# DP32G030 register map
File version: 1.0
CPU: CM0 r0p0, little endian, no MPU, no FPU, 4 interrupt priority bits
Registers are 32-bit, read-write, reset 0x0 unless marked. A register's access mark holds for its fields unless they carry their own. Offsets are from the block's base; [hi:lo] are bit positions; {n}, {i} and the like mark numbered series.

## AES128 — AES128 unit
Base 0x400BD000
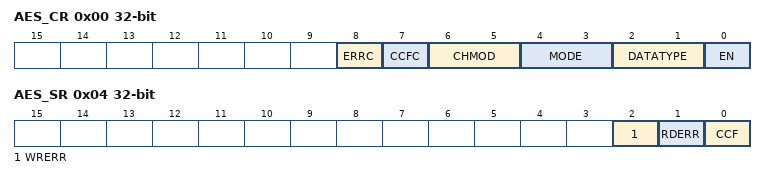
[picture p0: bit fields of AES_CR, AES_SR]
0x00 AES_CR access per field — AES control register
  [8] ERRC rw — Error Flag Clear Writing a 1 to this bit will clear the RDERR and WRERR flags. This bit reads low.
  [7] CCFC wo — The computation complete flag is cleared. This bit reads low.
  [6:5] CHMOD rw — AES link mode selection. 00: Electronic Codebook (ECB) 01: Cipher Block Link (CBC) 10: Counter mode (CTR) The AES link mode can only be changed when AES is disabled. Writing these bits when AES is enabled is prohibited to avoid unpredictable AES behaviour.
  [4:3] MODE rw — AES mode selection. 00: Mode 1: Encryption 01: Mode II: Key Derivation 10: Mode III: Decryption 11: Mode 4: Key Derivation + Decryption The mode of operation can only be changed when AES is disabled. Disable writing these bits when AES is enabled to avoid unpredictable AES behaviour. If CTR mode is selected, mode 4 is disabled. if the software attempts to configure mode 4 for CTR mode, it will force mode 3.
  [2:1] DATATYPE rw — Data type selection. 00: 32-bit data, no bit exchange. 01: 16-bit data or half-word, half-word exchange is performed. For example, the original data 0x764356AB, the value given to the encryption block is 0x56AB7643 10: 8-bit data or byte, all bytes are exchanged. For example, the original data is 0x764356AB and the value given to the encryption block is 0xAB564376. 11: 1-bit data. All bits are exchanged. For example, the original data is 0x00112233, the value given to the encryption block is 0xCC448800 The operation mode can be changed only when AES is disabled. It is forbidden to write these bits when AES is enabled to avoid some unpredictable AES behaviour.
  [0] EN rw — AES enable signal. The AES can be initialised at any time by resetting this bit: The AES is ready to start processing new blocks when EN is set. This bit is automatically cleared by hardware when the AES completes operation in mode 2 (key derivation).
0x04 AES_SR ro — AES status register
  [2] WRERR — Write Error Flag. This bit is set by hardware when an unexpected read operation from the AES_DINR register is detected (during the calculation or data entry phase). Software clears it by setting the ERRC bit in the AES_CR register. 0: No write error detected 1: Write error detected This flag has no effect on the AES, which continues to operate even if a WRERR interrupt is generated.
  [1] RDERR — Read Error Flag. This bit is set by hardware when an unexpected read operation from the AES_DOUTR register is detected (during the calculation or data entry phase). Software clears it by setting the ERRC bit in the AES_CR register. 0: No read error detected 1: Read error detected This flag has no effect on the AES, which continues to operate even if an RDERR interrupt is generated.
  [0] CCF — Calculation Completion Flag. If the CCFIE bit was previously set in the AES_CR register. Software clears it by setting the CCFC bit in the AES_CR register. 1: Calculation complete 0: Calculation not completed
0x08 AES_DINR — AES input data register
  [31:0] DINR — Input data register. In the input stage, this register must be written four times: - In mode 1 (encryption), four bytes must be written, representing data from MSB to LSB. - In mode 2 (key derivation), this register is not used, as it only involves key derivation calculation starting from the AES_KEYRx register. - In modes 3 (decryption) and 4 (key derivation + decryption), four bytes must be written, representing ciphertext from MSB to LSB. Note: This register must be accessed with a 32-bit data width.
0x0C AES_DOUTR ro — AES output data register
  [31:0] DOUTR — Data output register. This read-only register can be accessed four times to obtain the 128-bit output result once the CCF flag (calculation completion flag) is generated. In mode 1 (encryption), the four bytes read represent encrypted data from MSB to LSB. In mode 2 (key derivation), this register does not need to be read since the derived key is located in the AES_KEYRx register. In modes 3 (decryption) and 4 (key derivation + decryption), the four bytes read represent plaintext from MSB to LSB. Note that this register must be accessed with a 32-bit data width.
0x10 AES_KEYR0 — AES key register 0
  [31:0] KEYR — This key register must be written before enabling AES: In modes 1 (encryption), 2 (key derivation), and 4 (key derivation + decryption), the value to be written represents the encrypted secret key from LSB, meaning key [31:0]. In mode 3 (decryption), the value to be written represents the decrypted secret key [31:0]. When writing an encryption key to the register in this decryption mode, reading it before enabling AES returns the encrypted value. After setting the CCF flag, reading it returns the derived key. Reading this register when enabling AES returns an unpredictable value. Note: This register does not contain the derived key in mode 4 (derived key + decryption). It always contains the encrypted key value.
{0x10+4i} AES_KEYR{i} (i=1..3) — AES key register {i}
  [31:0] KEYR — Secret key register [{32i+31}:{32i}]
0x20 AES_IVR0 — AES Encryption starting point register 0
  [31:0] IVR — Initialization vector register [31:0]. Must be written before setting EN position 1 in the AES_CR register. The register value has no meaning in the following cases: - ECB mode (Electronic Codebook). - Key derivation in CTR or CBC modes. In CTR mode (Counter Mode), this register contains a 32-bit counter value. Reading this register while enabling AES returns a value of 0x00000000.
0x24 AES_IVR1 — AES Encryption starting point register 1
  [31:0] IVR — Initialization vector register [63:32]. In CTR mode (counter mode), this register contains random number values. When enabling AES at the same time, reading this register returns a value of 0x00000000.
0x28 AES_IVR2 — AES Encryption starting point register 2
  [31:0] IVR — Initialization vector register [95:64]. In CTR mode (counter mode), this register contains random number values. When enabling AES simultaneously, reading this register returns a value of 0x00000000.
0x2C AES_IVR3 — AES Encryption starting point register 3
  [31:0] IVR — Initialization vector register (MSB IVR [127:96]). In CTR mode (counter mode), this register contains random number values. When enabling AES simultaneously, reading this register returns a value of 0x00000000.
